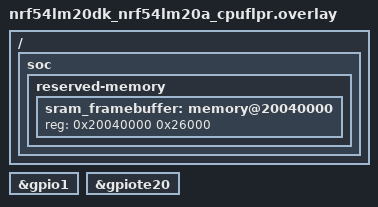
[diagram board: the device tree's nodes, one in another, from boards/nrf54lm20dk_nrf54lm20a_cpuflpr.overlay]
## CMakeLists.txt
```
cmake_minimum_required(VERSION 3.20.0)
find_package(Zephyr REQUIRED HINTS $ENV{ZEPHYR_BASE})

project(displaydriver)

target_sources(app PRIVATE
    src/main.c
    src/st7365.c
)

target_include_directories(app PRIVATE ${CMAKE_CURRENT_LIST_DIR}/../common)
```

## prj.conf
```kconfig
CONFIG_GPIO=y
CONFIG_SERIAL=y
CONFIG_CONSOLE=y
CONFIG_UART_CONSOLE=y
CONFIG_LOG=n
CONFIG_PM=n
```

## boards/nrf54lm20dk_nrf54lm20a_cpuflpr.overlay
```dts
/*
 * FLPR overlay for display driver
 *
 * - Enables GPIO Port 1 for 8-bit parallel display interface
 * - Defines shared framebuffer memory region (matches CPU app overlay)
 */

&gpio1 {
	status = "okay";
};

&gpiote20 {
	status = "okay";
};

/ {
	soc {
		reserved-memory {
			#address-cells = <1>;
			#size-cells = <1>;

			sram_framebuffer: memory@20040000 {
				reg = <0x20040000 0x26000>;
			};
		};
	};
};
```

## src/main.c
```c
/*
 * FLPR Display Driver - nRF54LM20-DK
 * Dedicated display streaming core with pluggable rendering modes.
 */

#include <zephyr/kernel.h>
#include "st7365.h"
#include "shared_display.h"

int main(void)
{
	st7365_init();

	st7365_fill_rgb565(RGB565_BLUE);
	k_msleep(300);
	st7365_fill_rgb565(RGB565_BLACK);

	SHARED_DISP->frame_count = 0;
	SHARED_DISP->fps = 0;
	/* render_mode is set by CPU — don't overwrite it here */
	SHARED_DISP->dirty_y_min = 0;
	SHARED_DISP->dirty_y_max = -1;
	SHARED_DISP->status = DISP_STATUS_READY;

	uint32_t fps_timer = k_uptime_get_32();
	uint32_t fps_frames = 0;

	while (1) {
		while (SHARED_DISP->status != DISP_STATUS_FRAME_READY) {
			/* spin */
		}

		SHARED_DISP->status = DISP_STATUS_FRAME_SENDING;

		uint32_t t0 = k_cyc_to_us_floor32(k_cycle_get_32());

		int y_min = SHARED_DISP->dirty_y_min;
		int y_max = SHARED_DISP->dirty_y_max;
		uint8_t rmode = SHARED_DISP->render_mode;

		if (y_min <= y_max && y_max < FB_HEIGHT) {
			switch (rmode) {
			case RMODE_TILES: {
				/* Tiles don't use y_min/y_max — scan full tile bitmap */
				uint32_t merged[TILE_WORDS];
				for (int i = 0; i < TILE_WORDS; i++) {
					merged[i] = SHARED_DISP->dirty_tiles[i];
				}
				st7365_stream_tiles(SHARED_DISP->framebuffer, merged);
				break;
			}
			case RMODE_PIXELS: {
				/* Merge row bitmaps for row filter */
				uint32_t merged_rows[DIRTY_WORDS];
				for (int i = 0; i < DIRTY_WORDS; i++) {
					merged_rows[i] = SHARED_DISP->dirty_rows[i] |
							 SHARED_DISP->prev_dirty_rows[i];
				}
				/* Read spans (already merged by CPU) */
				st7365_stream_spans(SHARED_DISP->framebuffer,
						    merged_rows,
						    (const struct row_span *)SHARED_DISP->dirty_spans,
						    y_min, y_max);
				break;
			}
			default: /* RMODE_ROWS */ {
				uint32_t merged[DIRTY_WORDS];
				for (int i = 0; i < DIRTY_WORDS; i++) {
					merged[i] = SHARED_DISP->dirty_rows[i] |
						    SHARED_DISP->prev_dirty_rows[i];
				}
				st7365_stream_dirty(SHARED_DISP->framebuffer,
						    merged, y_min, y_max);
				break;
			}
			}
		}

		uint32_t stream_us = k_cyc_to_us_floor32(k_cycle_get_32()) - t0;
		SHARED_DISP->flpr_stream_us = (uint16_t)(stream_us > 65535 ? 65535 : stream_us);
		SHARED_DISP->frame_count++;
		SHARED_DISP->status = DISP_STATUS_READY;

		fps_frames++;
		uint32_t now = k_uptime_get_32();
		uint32_t dt = now - fps_timer;
		if (dt >= 2000) {
			SHARED_DISP->fps = (uint16_t)(fps_frames * 1000 / dt);
			fps_frames = 0;
			fps_timer = now;
		}
	}

	return 0;
}
```

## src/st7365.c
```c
/*
 * ST7365 display driver — 8080 MCU parallel interface
 * FLPR (RISC-V) core, all pins on GPIO Port 1
 *
 * 16-bit mode: 2 GPIO writes per pixel (vs 4 in 8-bit mode)
 * DB0-7 on P1.00-07, DB8-15 on P1.10-17, gap at P1.08-09 (buttons)
 */

#include <zephyr/kernel.h>
#include <string.h>
#include <hal/nrf_gpio.h>
#include "st7365.h"

/* ------------------------------------------------------------------ */
/*  LUT: palette index → Port 1 pin pattern                          */
/* ------------------------------------------------------------------ */

#if DISPLAY_16BIT
/* 16-bit: one entry per palette index = full 16-bit pin pattern */
static uint32_t pixel_lut[256];
#else
/* 8-bit: hi/lo byte pin patterns */
static struct pixel_pins pixel_lut_8[256];
#endif

/* Full 256-color palette from shared header */
#include "display_palette.h"

/* ------------------------------------------------------------------ */
/*  Pin tables for configuration                                      */
/* ------------------------------------------------------------------ */

#if DISPLAY_16BIT
static const uint8_t data_pins[] = {
	/* DB0-DB4 = P1.03-P1.07 (same as 8-bit) */
	NRF_GPIO_PIN_MAP(1, 3),  NRF_GPIO_PIN_MAP(1, 4),
	NRF_GPIO_PIN_MAP(1, 5),  NRF_GPIO_PIN_MAP(1, 6),
	NRF_GPIO_PIN_MAP(1, 7),
	/* DB5-DB7 = P1.10-P1.12 (same as 8-bit) */
	NRF_GPIO_PIN_MAP(1, 10), NRF_GPIO_PIN_MAP(1, 11),
	NRF_GPIO_PIN_MAP(1, 12),
	/* DB8-DB11 = P1.16-P1.19 (new) */
	NRF_GPIO_PIN_MAP(1, 16), NRF_GPIO_PIN_MAP(1, 17),
	NRF_GPIO_PIN_MAP(1, 18), NRF_GPIO_PIN_MAP(1, 19),
	/* DB12-DB14 = P1.29-P1.31 (new) */
	NRF_GPIO_PIN_MAP(1, 29), NRF_GPIO_PIN_MAP(1, 30),
	NRF_GPIO_PIN_MAP(1, 31),
	/* DB15 = P1.00 (new) */
	NRF_GPIO_PIN_MAP(1, 0),
};
#else
static const uint8_t data_pins[] = {
	NRF_GPIO_PIN_MAP(1, 3),  NRF_GPIO_PIN_MAP(1, 4),
	NRF_GPIO_PIN_MAP(1, 5),  NRF_GPIO_PIN_MAP(1, 6),
	NRF_GPIO_PIN_MAP(1, 7),  NRF_GPIO_PIN_MAP(1, 10),
	NRF_GPIO_PIN_MAP(1, 11), NRF_GPIO_PIN_MAP(1, 12),
};
#endif

static const uint8_t ctrl_pins[] = {
	NRF_GPIO_PIN_MAP(1, PIN_CS),  NRF_GPIO_PIN_MAP(1, PIN_WR),
	NRF_GPIO_PIN_MAP(1, PIN_DC),  NRF_GPIO_PIN_MAP(1, PIN_RD),
	NRF_GPIO_PIN_MAP(1, PIN_RESET),
};

/* ------------------------------------------------------------------ */
/*  Low-level GPIO                                                    */
/* ------------------------------------------------------------------ */

static inline void pin_high(uint32_t mask)  { NRF_P1->OUTSET = mask; }
static inline void pin_low(uint32_t mask)   { NRF_P1->OUTCLR = mask; }

/* Write an 8-bit command/parameter byte over the bus.
 * In 16-bit mode, DB8-15 are cleared (don't-care for commands). */
static void write_byte(uint8_t val)
{
	uint32_t bits = byte_to_port1_pins(val);
	NRF_P1->OUTCLR = DATA_MASK | WR_MASK;
	NRF_P1->OUTSET = bits;
	NRF_P1->OUTSET = WR_MASK;
}

static void write_command(uint8_t cmd)
{
	pin_low(DC_MASK);
	write_byte(cmd);
	pin_high(DC_MASK);
}

static void write_data(uint8_t data)
{
	write_byte(data);
}

static void write_command_data(uint8_t cmd, const uint8_t *data, int len)
{
	write_command(cmd);
	for (int i = 0; i < len; i++) write_data(data[i]);
}

/* ------------------------------------------------------------------ */
/*  Init                                                              */
/* ------------------------------------------------------------------ */

static void configure_pins(void)
{
	for (int i = 0; i < ARRAY_SIZE(data_pins); i++) {
		nrf_gpio_cfg(data_pins[i], NRF_GPIO_PIN_DIR_OUTPUT,
			     NRF_GPIO_PIN_INPUT_DISCONNECT,
			     NRF_GPIO_PIN_NOPULL, NRF_GPIO_PIN_H0H1,
			     NRF_GPIO_PIN_NOSENSE);
	}
	for (int i = 0; i < ARRAY_SIZE(ctrl_pins); i++) {
		nrf_gpio_cfg(ctrl_pins[i], NRF_GPIO_PIN_DIR_OUTPUT,
			     NRF_GPIO_PIN_INPUT_DISCONNECT,
			     NRF_GPIO_PIN_NOPULL, NRF_GPIO_PIN_H0H1,
			     NRF_GPIO_PIN_NOSENSE);
	}
	pin_high(CS_MASK | WR_MASK | DC_MASK | RD_MASK | RESET_MASK);
	pin_low(DATA_MASK);
}

static void init_lut(void)
{
#if DISPLAY_16BIT
	memset(pixel_lut, 0, sizeof(pixel_lut));
	for (int i = 0; i < PAL_COUNT; i++) {
		pixel_lut[i] = rgb565_to_pins(palette_rgb565[i]);
	}
#else
	memset(pixel_lut_8, 0, sizeof(pixel_lut_8));
	for (int i = 0; i < PAL_COUNT; i++) {
		uint16_t rgb = palette_rgb565[i];
		pixel_lut_8[i].hi = byte_to_port1_pins(rgb >> 8);
		pixel_lut_8[i].lo = byte_to_port1_pins(rgb & 0xFF);
	}
#endif
}

static void hw_reset(void)
{
	pin_high(RESET_MASK);
	k_msleep(10);
	pin_low(RESET_MASK);
	k_msleep(20);
	pin_high(RESET_MASK);
	k_msleep(150);
}

static void set_window(int x0, int y0, int x1, int y1)
{
	/* Commands and parameters are ALWAYS 8-bit on DB0-DB7,
	 * even in 16-bit bus mode. Only pixel data uses full 16 bits. */
	uint8_t caset[] = { x0 >> 8, x0 & 0xFF, x1 >> 8, x1 & 0xFF };
	write_command_data(ST7365_CASET, caset, 4);
	uint8_t raset[] = { y0 >> 8, y0 & 0xFF, y1 >> 8, y1 & 0xFF };
	write_command_data(ST7365_RASET, raset, 4);
}

static void reset_window(void)
{
	set_window(0, 0, DISP_WIDTH - 1, DISP_HEIGHT - 1);
}

void st7365_init(void)
{
	configure_pins();
	init_lut();
	hw_reset();
	pin_low(CS_MASK);

	write_command(ST7365_SWRESET);
	k_msleep(150);
	write_command(ST7365_SLPOUT);
	k_msleep(150);

	/* Commands and params are always 8-bit, even in 16-bit bus mode */
	uint8_t colmod = COLMOD_RGB565;
	write_command_data(ST7365_COLMOD, &colmod, 1);

	uint8_t madctl = MADCTL_LANDSCAPE;
	write_command_data(ST7365_MADCTL, &madctl, 1);

	reset_window();

	write_command(ST7365_NORON);
	k_msleep(10);
	write_command(ST7365_INVON);
	write_command(ST7365_DISPON);
	k_msleep(50);
}

/* ------------------------------------------------------------------ */
/*  Fill                                                              */
/* ------------------------------------------------------------------ */

void st7365_fill_rgb565(uint16_t color)
{
	reset_window();
	write_command(ST7365_RAMWR);

#if DISPLAY_16BIT
	/* 16-bit: 3 writes per pixel with OUTCLR/OUTSET (safe) */
	uint32_t pins = rgb565_to_pins(color);
	for (int i = 0; i < DISP_PIXELS; i++) {
		NRF_P1->OUTCLR = DATA_MASK | WR_MASK;
		NRF_P1->OUTSET = pins;
		NRF_P1->OUTSET = WR_MASK;
	}
#else
	uint32_t hi = byte_to_port1_pins(color >> 8);
	uint32_t lo = byte_to_port1_pins(color & 0xFF);
	for (int i = 0; i < DISP_PIXELS; i++) {
		NRF_P1->OUTCLR = DATA_MASK | WR_MASK;
		NRF_P1->OUTSET = hi;
		NRF_P1->OUTSET = WR_MASK;
		NRF_P1->OUTCLR = DATA_MASK | WR_MASK;
		NRF_P1->OUTSET = lo;
		NRF_P1->OUTSET = WR_MASK;
	}
#endif
}

/* ------------------------------------------------------------------ */
/*  Stream full framebuffer                                           */
/* ------------------------------------------------------------------ */

void st7365_stream_framebuffer(const uint8_t *fb, int len)
{
	reset_window();
	write_command(ST7365_RAMWR);

#if DISPLAY_16BIT
	/* 16-bit: 3 writes per pixel, unrolled 4x = 12 per iteration */
	int i = 0, len4 = len & ~3;
	for (; i < len4; i += 4) {
		NRF_P1->OUTCLR = DATA_MASK | WR_MASK;
		NRF_P1->OUTSET = pixel_lut[fb[i]];
		NRF_P1->OUTSET = WR_MASK;
		NRF_P1->OUTCLR = DATA_MASK | WR_MASK;
		NRF_P1->OUTSET = pixel_lut[fb[i+1]];
		NRF_P1->OUTSET = WR_MASK;
		NRF_P1->OUTCLR = DATA_MASK | WR_MASK;
		NRF_P1->OUTSET = pixel_lut[fb[i+2]];
		NRF_P1->OUTSET = WR_MASK;
		NRF_P1->OUTCLR = DATA_MASK | WR_MASK;
		NRF_P1->OUTSET = pixel_lut[fb[i+3]];
		NRF_P1->OUTSET = WR_MASK;
	}
	for (; i < len; i++) {
		NRF_P1->OUTCLR = DATA_MASK | WR_MASK;
		NRF_P1->OUTSET = pixel_lut[fb[i]];
		NRF_P1->OUTSET = WR_MASK;
	}
#else
	/* 8-bit: OUTCLR/OUTSET — proven safe, doesn't stomp non-display pins */
	for (int i = 0; i < len; i++) {
		const struct pixel_pins *p = &pixel_lut_8[fb[i]];
		NRF_P1->OUTCLR = DATA_MASK | WR_MASK;
		NRF_P1->OUTSET = p->hi;
		NRF_P1->OUTSET = WR_MASK;
		NRF_P1->OUTCLR = DATA_MASK | WR_MASK;
		NRF_P1->OUTSET = p->lo;
		NRF_P1->OUTSET = WR_MASK;
	}
#endif
}

/* ------------------------------------------------------------------ */
/*  Stream dirty rows only                                            */
/* ------------------------------------------------------------------ */

void st7365_stream_dirty(const uint8_t *fb, const uint32_t *dirty_bits,
			 int y_min, int y_max)
{
	int y = y_min;

	while (y <= y_max) {
		while (y <= y_max && !(dirty_bits[y >> 5] & (1U << (y & 31)))) y++;
		if (y > y_max) break;

		int run_start = y;
		while (y <= y_max && (dirty_bits[y >> 5] & (1U << (y & 31)))) y++;
		int run_end = y - 1;

		set_window(0, run_start, DISP_WIDTH - 1, run_end);
		write_command(ST7365_RAMWR);

		const uint8_t *row = &fb[run_start * DISP_WIDTH];
		int npix = (run_end - run_start + 1) * DISP_WIDTH;

#if DISPLAY_16BIT
		int i = 0, npix4 = npix & ~3;
		for (; i < npix4; i += 4) {
			NRF_P1->OUTCLR = DATA_MASK | WR_MASK;
			NRF_P1->OUTSET = pixel_lut[row[i]];
			NRF_P1->OUTSET = WR_MASK;
			NRF_P1->OUTCLR = DATA_MASK | WR_MASK;
			NRF_P1->OUTSET = pixel_lut[row[i+1]];
			NRF_P1->OUTSET = WR_MASK;
			NRF_P1->OUTCLR = DATA_MASK | WR_MASK;
			NRF_P1->OUTSET = pixel_lut[row[i+2]];
			NRF_P1->OUTSET = WR_MASK;
			NRF_P1->OUTCLR = DATA_MASK | WR_MASK;
			NRF_P1->OUTSET = pixel_lut[row[i+3]];
			NRF_P1->OUTSET = WR_MASK;
		}
		for (; i < npix; i++) {
			NRF_P1->OUTCLR = DATA_MASK | WR_MASK;
			NRF_P1->OUTSET = pixel_lut[row[i]];
			NRF_P1->OUTSET = WR_MASK;
		}
#else
		/* 8-bit: OUTCLR/OUTSET */
		for (int i = 0; i < npix; i++) {
			const struct pixel_pins *p = &pixel_lut_8[row[i]];
			NRF_P1->OUTCLR = DATA_MASK | WR_MASK;
			NRF_P1->OUTSET = p->hi;
			NRF_P1->OUTSET = WR_MASK;
			NRF_P1->OUTCLR = DATA_MASK | WR_MASK;
			NRF_P1->OUTSET = p->lo;
			NRF_P1->OUTSET = WR_MASK;
		}
#endif
	}
}

/* ------------------------------------------------------------------ */
/*  Stream dirty tiles                                                */
/* ------------------------------------------------------------------ */

void st7365_stream_tiles(const uint8_t *fb, const uint32_t *tile_bits)
{
	for (int w = 0; w < TILE_WORDS; w++) {
		uint32_t bits = tile_bits[w];
		while (bits) {
			int bit = __builtin_ctz(bits);
			int idx = (w << 5) | bit;
			bits &= bits - 1;

			if (idx >= TILE_COUNT) continue;

			int tx = (idx % TILES_X) * TILE_W;
			int ty = (idx / TILES_X) * TILE_H;
			int tw = TILE_W;
			int th = TILE_H;
			if (tx + tw > DISP_WIDTH) tw = DISP_WIDTH - tx;
			if (ty + th > DISP_HEIGHT) th = DISP_HEIGHT - ty;

			set_window(tx, ty, tx + tw - 1, ty + th - 1);
			write_command(ST7365_RAMWR);

			for (int r = 0; r < th; r++) {
				const uint8_t *row = &fb[(ty + r) * DISP_WIDTH + tx];
#if DISPLAY_16BIT
				for (int c = 0; c < tw; c++) {
					NRF_P1->OUTCLR = DATA_MASK | WR_MASK;
					NRF_P1->OUTSET = pixel_lut[row[c]];
					NRF_P1->OUTSET = WR_MASK;
				}
#else
				for (int c = 0; c < tw; c++) {
					const struct pixel_pins *p = &pixel_lut_8[row[c]];
					NRF_P1->OUTCLR = DATA_MASK | WR_MASK;
					NRF_P1->OUTSET = p->hi;
					NRF_P1->OUTSET = WR_MASK;
					NRF_P1->OUTCLR = DATA_MASK | WR_MASK;
					NRF_P1->OUTSET = p->lo;
					NRF_P1->OUTSET = WR_MASK;
				}
#endif
			}
		}
	}
}

/* ------------------------------------------------------------------ */
/*  Stream dirty row spans (horizontal clipping)                      */
/* ------------------------------------------------------------------ */

void st7365_stream_spans(const uint8_t *fb, const uint32_t *row_bits,
			 const struct row_span *spans, int y_min, int y_max)
{
	for (int y = y_min; y <= y_max; y++) {
		if (!(row_bits[y >> 5] & (1U << (y & 31)))) continue;

		int x0 = spans[y].x_min;
		int x1 = spans[y].x_max;
		if (x0 > x1 || x0 >= DISP_WIDTH) continue;
		if (x1 >= DISP_WIDTH) x1 = DISP_WIDTH - 1;

		set_window(x0, y, x1, y);
		write_command(ST7365_RAMWR);

		const uint8_t *row = &fb[y * DISP_WIDTH + x0];
		int npix = x1 - x0 + 1;

#if DISPLAY_16BIT
		for (int i = 0; i < npix; i++) {
			NRF_P1->OUTCLR = DATA_MASK | WR_MASK;
			NRF_P1->OUTSET = pixel_lut[row[i]];
			NRF_P1->OUTSET = WR_MASK;
		}
#else
		for (int i = 0; i < npix; i++) {
			const struct pixel_pins *p = &pixel_lut_8[row[i]];
			NRF_P1->OUTCLR = DATA_MASK | WR_MASK;
			NRF_P1->OUTSET = p->hi;
			NRF_P1->OUTSET = WR_MASK;
			NRF_P1->OUTCLR = DATA_MASK | WR_MASK;
			NRF_P1->OUTSET = p->lo;
			NRF_P1->OUTSET = WR_MASK;
		}
#endif
	}
}
```

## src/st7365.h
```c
#ifndef ST7365_H
#define ST7365_H

#include <stdint.h>
#include <stdbool.h>
#include "shared_display.h"

/*
 * ST7365 display driver for UEED035HV-RX40-L001
 * 480x320 landscape, 8080 MCU parallel interface
 * All pins on GPIO Port 1 for fast register writes from FLPR
 *
 * Set DISPLAY_16BIT to 1 for 16-bit bus (2 GPIO writes/pixel)
 * Set DISPLAY_16BIT to 0 for 8-bit bus  (4 GPIO writes/pixel)
 */

#define DISPLAY_16BIT   1

/* Screen dimensions (landscape) */
#define DISP_WIDTH      480
#define DISP_HEIGHT     320
#define DISP_PIXELS     (DISP_WIDTH * DISP_HEIGHT)

/* ------------------------------------------------------------------ */
/*  Pin mapping                                                       */
/* ------------------------------------------------------------------ */

#if DISPLAY_16BIT

/*
 * 16-bit data bus — extends the proven 8-bit pinout with 8 more pins.
 *
 *   DB0-DB4  = P1.03-P1.07  (bits 3-7)     — same as 8-bit
 *   DB5-DB7  = P1.10-P1.12  (bits 10-12)   — same as 8-bit
 *   DB8      = P1.16  (bit 16)
 *   DB9      = P1.17  (bit 17)
 *   DB10     = P1.18  (bit 18)
 *   DB11     = P1.19  (bit 19)
 *   DB12     = P1.29  (bit 29)
 *   DB13     = P1.30  (bit 30)
 *   DB14     = P1.31  (bit 31)
 *   DB15     = P1.00  (bit 0)
 *
 * Control: same as 8-bit (CS=13, WR=14, DC=15, RD=23, RESET=24)
 */

#define DATA_MASK  ( (1UL << 0)              /* DB15=P1.00 */ \
                   | (0x1FUL << 3)           /* DB0-4=P1.03-07 */ \
                   | (0x07UL << 10)          /* DB5-7=P1.10-12 */ \
                   | (0x0FUL << 16)          /* DB8-11=P1.16-19 */ \
                   | (0x07UL << 29) )        /* DB12-14=P1.29-31 */

#define PIN_CS          13
#define PIN_WR          14
#define PIN_DC          15
#define PIN_RD          23
#define PIN_RESET       24

/*
 * Convert RGB565 to Port 1 pin positions.
 * Scattered mapping — but only computed once per pixel via LUT.
 *
 * RGB565 bit -> Display DB -> Port 1 bit
 *   0-4      -> DB0-4     -> 3-7    (shift left 3)
 *   5-7      -> DB5-7     -> 10-12  (shift left 5)
 *   8-11     -> DB8-11    -> 16-19  (shift left 8)
 *   12-14    -> DB12-14   -> 29-31  (shift left 17)
 *   15       -> DB15      -> 0      (shift right 15)
 */
static inline uint32_t rgb565_to_pins(uint16_t rgb)
{
	return ((uint32_t)(rgb & 0x001F) << 3)     /* DB0-4  -> P1.03-07 */
	     | ((uint32_t)(rgb & 0x00E0) << 5)     /* DB5-7  -> P1.10-12 */
	     | ((uint32_t)(rgb & 0x0F00) << 8)     /* DB8-11 -> P1.16-19 */
	     | ((uint32_t)(rgb & 0x7000) << 17)    /* DB12-14-> P1.29-31 */
	     | ((uint32_t)(rgb >> 15) & 0x01);     /* DB15   -> P1.00    */
}

/* Command/param byte: only DB0-DB7 (same mapping as 8-bit mode) */
static inline uint32_t byte_to_port1_pins(uint8_t byte)
{
	return ((uint32_t)(byte & 0x1F) << 3)
	     | ((uint32_t)((byte >> 5) & 0x07) << 10);
}

#else /* 8-bit mode */

/*
 * 8-bit data bus:
 *   DB0-DB4 = P1.03-P1.07  (Port 1 bits 3-7)
 *   DB5-DB7 = P1.10-P1.12  (Port 1 bits 10-12)
 *
 * Control signals:
 *   CS    = P1.13
 *   WR    = P1.14
 *   DC    = P1.15
 *   RD    = P1.23
 *   RESET = P1.24
 */

#define DATA_LO_MASK    (0x1FUL << 3)       /* P1.03-P1.07 */
#define DATA_HI_MASK    (0x07UL << 10)      /* P1.10-P1.12 */
#define DATA_MASK       (DATA_LO_MASK | DATA_HI_MASK)

/* Original 8-bit control pins (proven working) */
#define PIN_CS          13
#define PIN_WR          14
#define PIN_DC          15
#define PIN_RD          23
#define PIN_RESET       24

static inline uint32_t byte_to_port1_pins(uint8_t byte)
{
	return ((uint32_t)(byte & 0x1F) << 3)
	     | ((uint32_t)((byte >> 5) & 0x07) << 10);
}

#endif /* DISPLAY_16BIT */

/* Control pin masks (same for both modes, just different pin numbers) */
#define CS_MASK         (1UL << PIN_CS)
#define WR_MASK         (1UL << PIN_WR)
#define DC_MASK         (1UL << PIN_DC)
#define RD_MASK         (1UL << PIN_RD)
#define RESET_MASK      (1UL << PIN_RESET)

#define CTRL_MASK       (CS_MASK | WR_MASK | DC_MASK | RD_MASK | RESET_MASK)
#define ALL_DISP_MASK   (DATA_MASK | CTRL_MASK)

/* ------------------------------------------------------------------ */
/*  ST7365 Commands                                                   */
/* ------------------------------------------------------------------ */

#define ST7365_NOP      0x00
#define ST7365_SWRESET  0x01
#define ST7365_SLPOUT   0x11
#define ST7365_NORON    0x13
#define ST7365_INVOFF   0x20
#define ST7365_INVON    0x21
#define ST7365_DISPON   0x29
#define ST7365_DISPOFF  0x28
#define ST7365_CASET    0x2A
#define ST7365_RASET    0x2B
#define ST7365_RAMWR    0x2C
#define ST7365_MADCTL   0x36
#define ST7365_COLMOD   0x3A

/* MADCTL bits */
#define MADCTL_MY       0x80
#define MADCTL_MX       0x40
#define MADCTL_MV       0x20
#define MADCTL_ML       0x10
#define MADCTL_BGR      0x08
#define MADCTL_MH       0x04

#define MADCTL_LANDSCAPE    (MADCTL_MV | MADCTL_MX | MADCTL_MY | MADCTL_BGR)
#define COLMOD_RGB565   0x55

/* 16-color palette (index 0 = transparent/black) */
#define PAL_TRANSPARENT 0
#define PAL_WHITE       1
#define PAL_BLACK       2
#define PAL_RED         3
#define PAL_YELLOW      4
#define PAL_ORANGE      5
#define PAL_GREEN       6
#define PAL_CYAN        7
#define PAL_BLUE        8
#define PAL_DKGRAY      9
#define PAL_MDGRAY      10
#define PAL_LTGRAY      11
#define PAL_DKRED       12
#define PAL_DKGREEN     13
#define PAL_DKBLUE      14
#define PAL_MAGENTA     15
#define PAL_COUNT       16

#define RGB565_BLACK    0x0000
#define RGB565_WHITE    0xFFFF
#define RGB565_RED      0xF800
#define RGB565_YELLOW   0xFFE0
#define RGB565_ORANGE   0xFC00
#define RGB565_GREEN    0x07E0
#define RGB565_CYAN     0x07FF
#define RGB565_BLUE     0x001F
#define RGB565_DKGRAY   0x4208
#define RGB565_MDGRAY   0x8410
#define RGB565_LTGRAY   0xC618
#define RGB565_DKRED    0x8000
#define RGB565_DKGREEN  0x0400
#define RGB565_DKBLUE   0x0010
#define RGB565_MAGENTA  0xF81F

/* Precomputed pixel pin data */
struct pixel_pins {
	uint32_t hi;
	uint32_t lo;
};

/* Public API */
void st7365_init(void);
void st7365_fill_rgb565(uint16_t color);
void st7365_begin_pixels(void);
void st7365_stream_framebuffer(const uint8_t *fb, int len);
void st7365_stream_dirty(const uint8_t *fb, const uint32_t *dirty_bits,
			 int y_min, int y_max);
void st7365_stream_tiles(const uint8_t *fb, const uint32_t *tile_bits);
void st7365_stream_spans(const uint8_t *fb, const uint32_t *row_bits,
			 const struct row_span *spans, int y_min, int y_max);

#endif /* ST7365_H */
```
